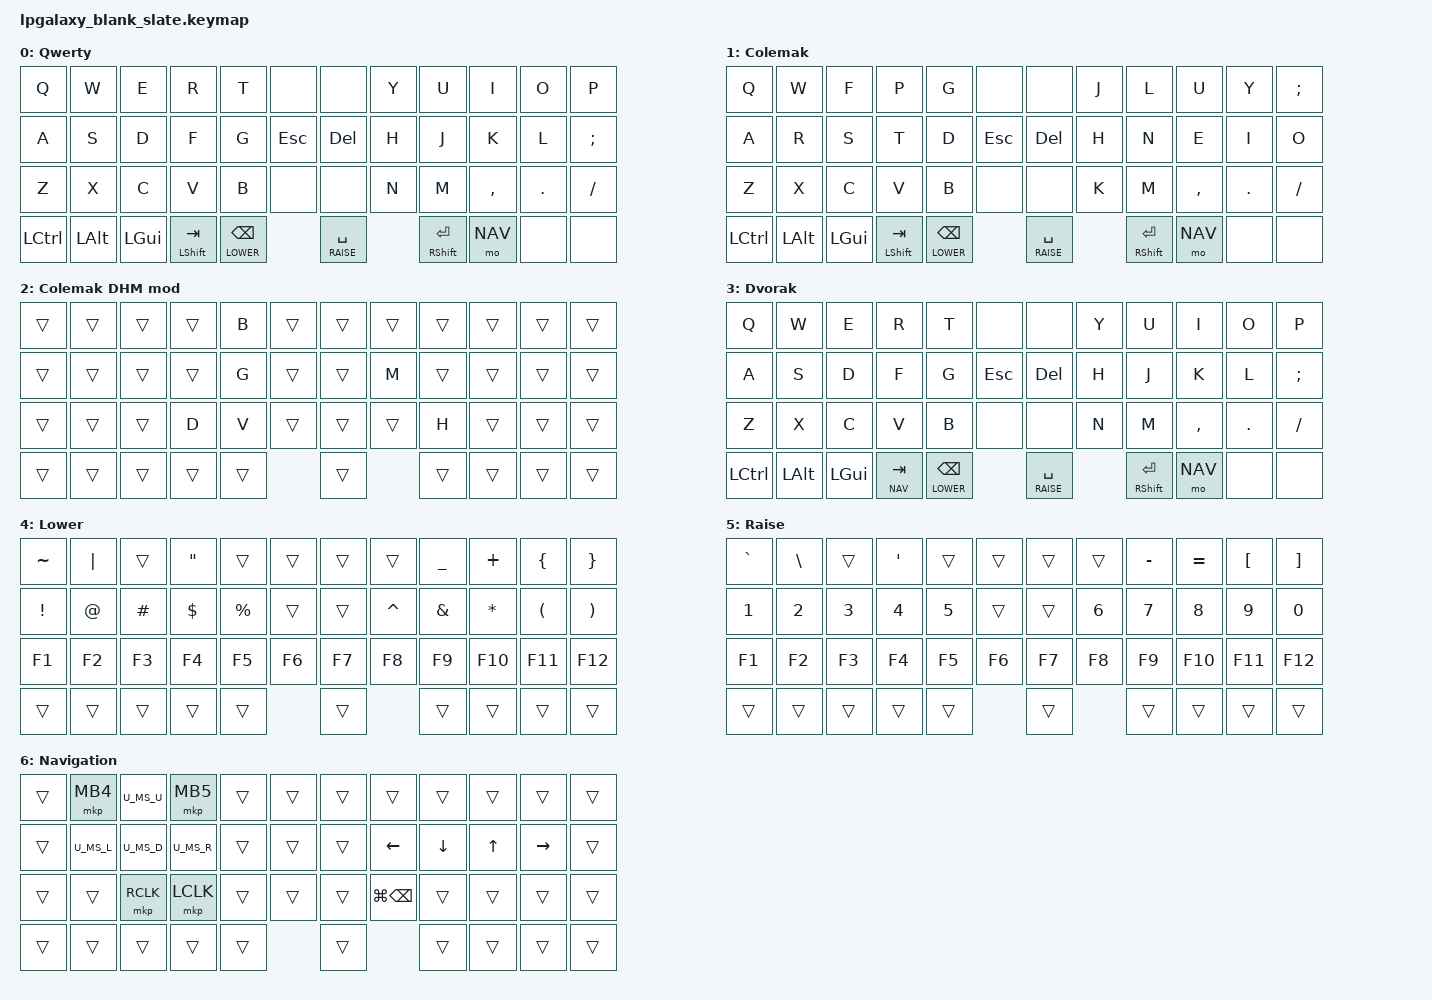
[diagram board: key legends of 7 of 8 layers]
#include <behaviors.dtsi>
#include <dt-bindings/zmk/keys.h>
#include <dt-bindings/zmk/bt.h>
#include <dt-bindings/zmk/outputs.h>
#include "mouse.dtsi"

#define QWERTY_BASE 1

#define TBLE_ORTHO   1

#define QWERTY 0
#define COLEMAK 1
#define DHM_MOD 2
#define DVORAK 3
#define LOWER 4
#define RAISE 5
#define NAV 6
#define ADJUST 7
#define BT(n) BT_SEL n

// Using layer taps on thumbs, having quick tap as well helps w/ repeating space/backspace
&lt { quick_tap_ms = <200>; };

/ {
    chosen {
       zmk,matrix_transform = &dual_2u_transform;
    };
    
    // Activate ADJUST layer by pressing raise and lower
    conditional_layers {
        compatible = "zmk,conditional-layers";
        adjust_layer {
            if-layers = <LOWER RAISE>;
            then-layer = <ADJUST>;
        };
    };

    keymap {
        compatible = "zmk,keymap";

        qwerty {
            label = "Qwerty";
            bindings = <
                &kp Q     &kp W    &kp E    &kp R          &kp T          &none   &none           &kp Y &kp U          &kp I     &kp O   &kp P
                &kp A     &kp S    &kp D    &kp F          &kp G          &kp ESC &kp DEL         &kp H &kp J          &kp K     &kp L   &kp SEMI
                &kp Z     &kp X    &kp C    &kp V          &kp B          &none   &none           &kp N &kp M          &kp COMMA &kp DOT &kp FSLH  
                &kp LCTRL &kp LALT &kp LGUI &mt LSHIFT TAB &lt LOWER BSPC         &lt RAISE SPACE       &mt RSHIFT RET &mo NAV   &none   &none
            >;
        };
        
        colemak {
            label = "Colemak";
            bindings = <
                &kp Q     &kp W    &kp F    &kp P          &kp G          &none   &none           &kp J &kp L          &kp U     &kp Y   &kp SEMI
                &kp A     &kp R    &kp S    &kp T          &kp D          &kp ESC &kp DEL         &kp H &kp N          &kp E     &kp I   &kp O
                &kp Z     &kp X    &kp C    &kp V          &kp B          &none   &none           &kp K &kp M          &kp COMMA &kp DOT &kp FSLH  
                &kp LCTRL &kp LALT &kp LGUI &mt LSHIFT TAB &lt LOWER BSPC         &lt RAISE SPACE       &mt RSHIFT RET &mo NAV   &none   &none
            >;
        };

        dhm_mod {
            label = "Colemak DHM mod";
            bindings = <
                &trans  &trans  &trans  &trans  &kp B   &trans  &trans  &trans  &trans  &trans  &trans  &trans
                &trans  &trans  &trans  &trans  &kp G   &trans  &trans  &kp M   &trans  &trans  &trans  &trans
                &trans  &trans  &trans  &kp D   &kp V   &trans  &trans  &trans  &kp H   &trans  &trans  &trans
                &trans  &trans  &trans  &trans  &trans          &trans          &trans  &trans  &trans  &trans
            >;
        };

        // needs to be updated still
        dvorak {
            label = "Dvorak";
            bindings = <
                &kp Q     &kp W    &kp E    &kp R       &kp T          &none   &none           &kp Y &kp U          &kp I     &kp O   &kp P
                &kp A     &kp S    &kp D    &kp F       &kp G          &kp ESC &kp DEL         &kp H &kp J          &kp K     &kp L   &kp SEMI
                &kp Z     &kp X    &kp C    &kp V       &kp B          &none   &none           &kp N &kp M          &kp COMMA &kp DOT &kp FSLH  
                &kp LCTRL &kp LALT &kp LGUI &lt NAV TAB &lt LOWER BSPC         &lt RAISE SPACE       &mt RSHIFT RET &mo NAV   &none   &none
            >;
        };

        lower {
            label = "Lower";
            bindings = <
                &kp TILDE &kp PIPE &trans   &kp DQT  &trans    &trans &trans &trans    &kp UNDER &kp PLUS  &kp LBRC &kp RBRC
                &kp EXCL  &kp AT   &kp HASH &kp DLLR &kp PRCNT &trans &trans &kp CARET &kp AMPS  &kp ASTRK &kp LPAR &kp RPAR
                &kp F1    &kp F2   &kp F3   &kp F4   &kp F5    &kp F6 &kp F7 &kp F8    &kp F9    &kp F10   &kp F11  &kp F12
                &trans    &trans   &trans   &trans   &trans           &trans           &trans    &trans    &trans   &trans
            >;
        };

        raise {
            label = "Raise";
            bindings = <
                &kp GRAVE &kp BSLH &trans &kp SQT &trans &trans &trans &trans &kp MINUS &kp EQUAL &kp LBKT &kp RBKT
                &kp N1    &kp N2   &kp N3 &kp N4  &kp N5 &trans &trans &kp N6 &kp N7    &kp N8    &kp N9   &kp N0
                &kp F1    &kp F2   &kp F3 &kp F4  &kp F5 &kp F6 &kp F7 &kp F8 &kp F9    &kp F10   &kp F11  &kp F12
                &trans    &trans   &trans &trans  &trans        &trans        &trans    &trans    &trans   &trans
            >;
        };

        nav {
            label = "Navigation";
            bindings = <
                &trans &mkp MB4 U_MS_U    &mkp MB5  &trans  &trans &trans &trans       &trans   &trans &trans    &trans
                &trans U_MS_L   U_MS_D    U_MS_R    &trans  &trans &trans &kp LEFT     &kp DOWN &kp UP &kp RIGHT &trans
                &trans &trans   &mkp RCLK &mkp LCLK &trans  &trans &trans &kp LG(BSPC) &trans   &trans &trans    &trans
                &trans &trans   &trans    &trans    &trans         &trans              &trans   &trans &trans    &trans
            >;
        };

        adjust {
            label = "Adjust";
            bindings = <
                &kp C_BRI_DN &kp C_BRI_UP &kp C_AC_DESKTOP_SHOW_ALL_WINDOWS &kp C_AC_SEARCH &kp C_VOICE_COMMAND &trans &kp C_PREV &kp C_PP &kp C_NEXT  &kp C_MUTE  &kp C_VOL_DN &kp C_VOL_UP
                &bt BT(0)    &bt BT(1)    &bt BT(2)                         &bt BT(3)       &bt BT(4)           &trans &trans     &trans   &to QWERTY  &to COLEMAK &to DVORAK   &trans
                &trans       &trans       &trans                            &trans          &trans              &trans &trans     &trans   &trans      &trans      &trans       &trans
                &bt BT_CLR   &trans       &trans                            &trans          &trans                     &trans              &bootloader &sys_reset  &trans       &soft_off
            >;
        };
    };
};

